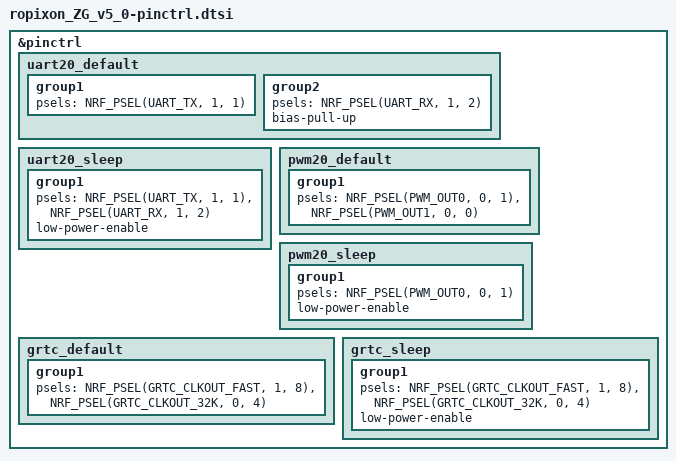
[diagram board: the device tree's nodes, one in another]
/*
 * Copyright (c) 2024 Ropixon
 * SPDX-License-Identifier: Apache-2.0
 */

&pinctrl {
    /omit-if-no-ref/ uart20_default: uart20_default {
        group1 {
            psels = <NRF_PSEL(UART_TX, 1, 1)>;
        };
        group2 {
            psels = <NRF_PSEL(UART_RX, 1, 2)>;
            bias-pull-up;
        };
    };

    /omit-if-no-ref/ uart20_sleep: uart20_sleep {
        group1 {
            psels = <NRF_PSEL(UART_TX, 1, 1)>,
                <NRF_PSEL(UART_RX, 1, 2)>;
            low-power-enable;
        };
    };

    /omit-if-no-ref/ pwm20_default: pwm20_default {
        group1 {
            psels = <NRF_PSEL(PWM_OUT0, 0, 1)>, <NRF_PSEL(PWM_OUT1, 0, 0)>;
        };
    };
    /omit-if-no-ref/ pwm20_sleep: pwm20_sleep {
        group1 {
            psels = <NRF_PSEL(PWM_OUT0, 0, 1)>;
            low-power-enable;
        };
    };

    /omit-if-no-ref/ grtc_default: grtc_default {
        group1 {
            psels = <NRF_PSEL(GRTC_CLKOUT_FAST, 1, 8)>,
                <NRF_PSEL(GRTC_CLKOUT_32K, 0, 4)>;
        };
    };

    /omit-if-no-ref/ grtc_sleep: grtc_sleep {
        group1 {
            psels = <NRF_PSEL(GRTC_CLKOUT_FAST, 1, 8)>,
                <NRF_PSEL(GRTC_CLKOUT_32K, 0, 4)>;
            low-power-enable;
        };
    };
};
